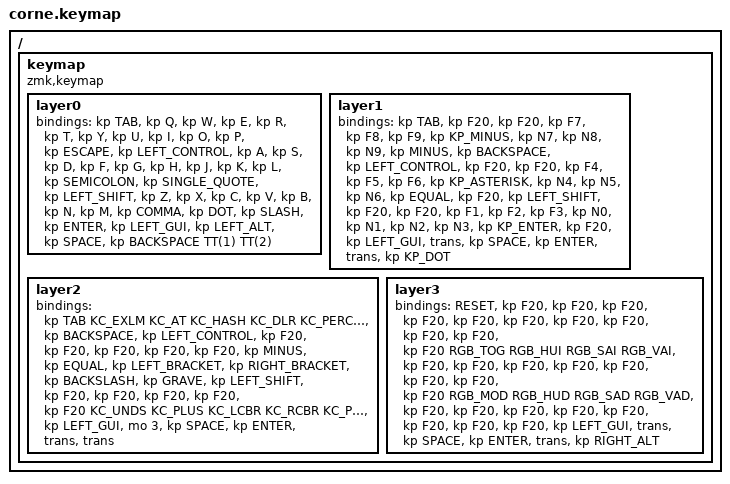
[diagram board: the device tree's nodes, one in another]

  /*
  * Copyright (c) 2020 The ZMK Contributors
  *
  * SPDX-License-Identifier: MIT
  */

  #include <behaviors.dtsi>
  #include <dt-bindings/zmk/keys.h>
  #include <dt-bindings/zmk/bt.h>
  #include <dt-bindings/zmk/ext_power.h>

  / {
    keymap {
      compatible = "zmk,keymap";
  layer0 {
          bindings = <
          &kp TAB &kp Q &kp W &kp E &kp R &kp T &kp Y &kp U &kp I &kp O &kp P &kp ESCAPE &kp LEFT_CONTROL &kp A &kp S &kp D &kp F &kp G &kp H &kp J &kp K &kp L &kp SEMICOLON &kp SINGLE_QUOTE &kp LEFT_SHIFT &kp Z &kp X &kp C &kp V &kp B &kp N &kp M &kp COMMA &kp DOT &kp SLASH &kp ENTER &kp LEFT_GUI &kp LEFT_ALT &kp SPACE &kp BACKSPACE TT(1) TT(2)
          >;
        };layer1 {
          bindings = <
          &kp TAB &kp F20 &kp F20 &kp F7 &kp F8 &kp F9 &kp KP_MINUS &kp N7 &kp N8 &kp N9 &kp MINUS &kp BACKSPACE &kp LEFT_CONTROL &kp F20 &kp F20 &kp F4 &kp F5 &kp F6 &kp KP_ASTERISK &kp N4 &kp N5 &kp N6 &kp EQUAL &kp F20 &kp LEFT_SHIFT &kp F20 &kp F20 &kp F1 &kp F2 &kp F3 &kp N0 &kp N1 &kp N2 &kp N3 &kp KP_ENTER &kp F20 &kp LEFT_GUI &trans &kp SPACE &kp ENTER &trans &kp KP_DOT
          >;
        };layer2 {
          bindings = <
          &kp TAB KC_EXLM KC_AT KC_HASH KC_DLR KC_PERC KC_CIRC KC_AMPR KC_ASTR KC_LPRN KC_RPRN &kp BACKSPACE &kp LEFT_CONTROL &kp F20 &kp F20 &kp F20 &kp F20 &kp F20 &kp MINUS &kp EQUAL &kp LEFT_BRACKET &kp RIGHT_BRACKET &kp BACKSLASH &kp GRAVE &kp LEFT_SHIFT &kp F20 &kp F20 &kp F20 &kp F20 &kp F20 KC_UNDS KC_PLUS KC_LCBR KC_RCBR KC_PIPE KC_TILD &kp LEFT_GUI &mo 3 &kp SPACE &kp ENTER &trans &trans
          >;
        };layer3 {
          bindings = <
          RESET &kp F20 &kp F20 &kp F20 &kp F20 &kp F20 &kp F20 &kp F20 &kp F20 &kp F20 &kp F20 &kp F20 RGB_TOG RGB_HUI RGB_SAI RGB_VAI &kp F20 &kp F20 &kp F20 &kp F20 &kp F20 &kp F20 &kp F20 &kp F20 RGB_MOD RGB_HUD RGB_SAD RGB_VAD &kp F20 &kp F20 &kp F20 &kp F20 &kp F20 &kp F20 &kp F20 &kp F20 &kp LEFT_GUI &trans &kp SPACE &kp ENTER &trans &kp RIGHT_ALT
          >;
        };
    };
  };
  
